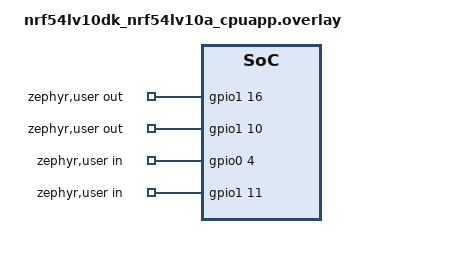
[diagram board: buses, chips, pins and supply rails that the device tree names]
/*
 * Copyright (c) 2025 Nordic Semiconductor ASA
 *
 * SPDX-License-Identifier: LicenseRef-Nordic-5-Clause
 */

/ {
	/* Test requirements:
	 * out-gpios[0] wire connected with in-gpios[0],
	 * out-gpios[1] wire connected with in-gpios[1],
	 * etc.
	 * Output-input GPIO pair must have identical active level flag.
	 */
	zephyr,user {
		out-gpios = <&gpio1 16 GPIO_ACTIVE_HIGH>, <&gpio1 10 GPIO_ACTIVE_HIGH>;
		in-gpios = <&gpio0 4 GPIO_ACTIVE_HIGH>, <&gpio1 11 GPIO_ACTIVE_HIGH>;
	};
};

&gpio0 {
	status = "okay";
};

&gpio1 {
	status = "okay";
};

/* Enable interrupt from GPIO P1 events. */
&gpiote20 {
	status = "okay";
};

/* Enable interrupt from GPIO P0 events. */
&gpiote30 {
	status = "okay";
};
